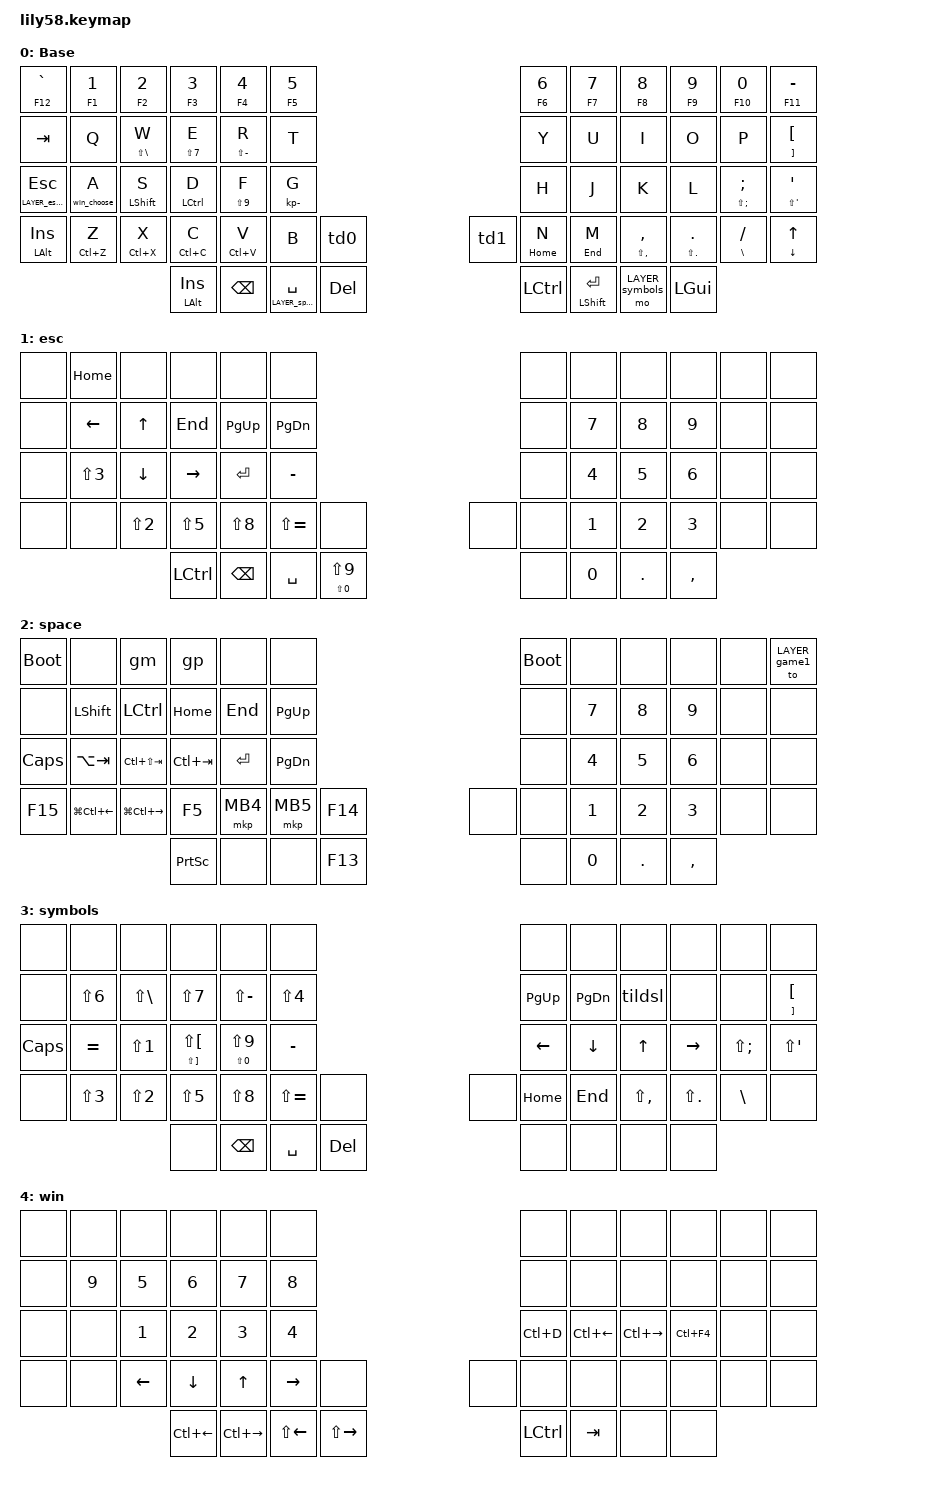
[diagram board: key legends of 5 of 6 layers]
/*
 * Copyright (c) 2020 The ZMK Contributors
 *
 * SPDX-License-Identifier: MIT
 */

#include <behaviors.dtsi>
#include <dt-bindings/zmk/keys.h>
#include <dt-bindings/zmk/bt.h>
#include <dt-bindings/zmk/ext_power.h>
#include <dt-bindings/zmk/pointing.h>

#define LAYER_Base 0
#define LAYER_esc_hold 1
#define LAYER_space_hold 2
#define LAYER_symbols 3
#define LAYER_a_windows 4
#define LAYER_game1 5

/* Key positions */

#define POS_LH_C1R1 0
#define POS_LH_C2R1 1
#define POS_LH_C3R1 2
#define POS_LH_C4R1 3
#define POS_LH_C5R1 4
#define POS_LH_C6R1 5
#define POS_RH_C1R1 6
#define POS_RH_C2R1 7
#define POS_RH_C3R1 8
#define POS_RH_C4R1 9
#define POS_RH_C5R1 10
#define POS_RH_C6R1 11
#define POS_LH_C1R2 12
#define POS_LH_C2R2 13
#define POS_LH_C3R2 14
#define POS_LH_C4R2 15
#define POS_LH_C5R2 16
#define POS_LH_C6R2 17
#define POS_RH_C1R2 18
#define POS_RH_C2R2 19
#define POS_RH_C3R2 20
#define POS_RH_C4R2 21
#define POS_RH_C5R2 22
#define POS_RH_C6R2 23
#define POS_LH_C1R3 24
#define POS_LH_C2R3 25
#define POS_LH_C3R3 26
#define POS_LH_C4R3 27
#define POS_LH_C5R3 28
#define POS_LH_C6R3 29
#define POS_RH_C1R3 30
#define POS_RH_C2R3 31
#define POS_RH_C3R3 32
#define POS_RH_C4R3 33
#define POS_RH_C5R3 34
#define POS_RH_C6R3 35
#define POS_LH_C1R4 36
#define POS_LH_C2R4 37
#define POS_LH_C3R4 38
#define POS_LH_C4R4 39
#define POS_LH_C5R4 40
#define POS_LH_C6R4 41
#define POS_RH_C1R4 42
#define POS_RH_C2R4 43
#define POS_RH_C3R4 44
#define POS_RH_C4R4 45
#define POS_RH_C5R4 46
#define POS_RH_C6R4 47
#define POS_LH_T1 48
#define POS_LH_T2 49
#define POS_LH_T3 50
#define POS_LH_T4 51
#define POS_LH_T5 52
#define POS_RH_T1 53
#define POS_RH_T2 54
#define POS_RH_T3 55
#define POS_RH_T4 56
#define POS_RH_T5 57

&mt {
    flavor = "tap-preferred";
    quick-tap-ms = <200>;
    require-prior-idle-ms = <100>;
    tapping-term-ms = <250>;
};

&lt {
    flavor = "tap-preferred";
    quick-tap-ms = <200>;
    require-prior-idle-ms = <100>;
};

/* Custom Defined Behaviors */
/ {
behaviors {
        td0: tap_dance_0 {
            compatible = "zmk,behavior-tap-dance";
            #binding-cells = <0>;
            tapping-term-ms = <200>;
            bindings = <&kp LC(LS(N1))>, <&kp LS(LG(LEFT))>, <&plapprove>;
        };
        td1: tap_dance_1 {
            compatible = "zmk,behavior-tap-dance";
            #binding-cells = <0>;
            tapping-term-ms = <200>;
            bindings = <&mkp LCLK>, <&lockwin>, <&plapprove>;
        };
};
};

/* Automatically generated macro definitions */
/ {
    macros {

        // windows and keypress
        win_choose: win_choose {
            label = "&WIN_CHOOSE";
            compatible = "zmk,behavior-macro";
            #binding-cells = <0>;
            tap-ms = <0>;
            wait-ms = <0>;
            bindings = <&macro_press>
                , <&mo LAYER_a_windows>
                , <&kp LGUI>
                , <&macro_pause_for_release>
                , <&macro_release>
                , <&mo LAYER_a_windows>
                , <&kp LGUI>;
        };

        // lock windows
        lockwin: lockwin {
            label = "&LOCKWIN";
            compatible = "zmk,behavior-macro";
            #binding-cells = <0>;
            tap-ms = <10>;
            wait-ms = <0>;
            bindings = <&macro_press>
                , <&kp LCTRL>
                , <&kp LALT>
                , <&macro_tap>
                , <&kp END>
                , <&macro_wait_time 2000>
                , <&macro_tap>
                , <&none>
                , <&macro_wait_time 1>
                , <&macro_release>
                , <&kp LALT>
                , <&kp LCTRL>
                , <&macro_tap>
                , <&kp RET>;
        };

        // please approve paste
        plapprove: plapprove {
            label = "&PLAPPROVE";
            compatible = "zmk,behavior-macro";
            #binding-cells = <0>;
            tap-ms = <20>;
            wait-ms = <30>;
            bindings = <&macro_tap>
                , <&kp P>
                , <&kp L>
                , <&kp E>
                , <&kp A>
                , <&kp S>
                , <&kp E>
                , <&kp SPACE>
                , <&kp A>
                , <&kp P>
                , <&kp P>
                , <&kp R>
                , <&kp O>
                , <&kp V>
                , <&kp E>
                , <&kp SPACE>
                , <&macro_tap>
                , <&kp LC(V)>
                , <&macro_wait_time 30>
                , <&macro_tap>
                , <&kp RET>;
        };

        // tilde slash
        tildsl: tildsl {
            label = "&TILDSL";
            compatible = "zmk,behavior-macro";
            #binding-cells = <0>;
            tap-ms = <30>;
            wait-ms = <30>;
            bindings = <&macro_tap>
                , <&kp LS(GRAVE)>
                , <&kp FSLH>;
        };

        // gp
        gp: gp {
            label = "&GP";
            compatible = "zmk,behavior-macro";
            #binding-cells = <0>;
            tap-ms = <30>;
            wait-ms = <30>;
            bindings = <&macro_tap>
                , <&kp G>
                , <&kp P>;
        };

        // gm
        gm: gm {
            label = "&GM";
            compatible = "zmk,behavior-macro";
            #binding-cells = <0>;
            tap-ms = <30>;
            wait-ms = <30>;
            bindings = <&macro_tap>
                , <&kp G>
                , <&kp M>;
        };
    };
};

/* Automatically generated behavior definitions */
/ {
    behaviors {


        // shift enter
        se: se {
            compatible = "zmk,behavior-hold-tap";
            #binding-cells = <2>;
            tapping-term-ms = <140>;
            bindings = <&kp>, <&kp>;
            quick-tap-ms = <150>;
        };

        // hold windows key and go to layer with numbers
        mtwc: mtwc {
            compatible = "zmk,behavior-hold-tap";
            #binding-cells = <2>;
            tapping-term-ms = <250>;
            bindings = <&win_choose>, <&kp>;
            flavor = "tap-preferred";
            quick-tap-ms = <200>;
            require-prior-idle-ms = <100>;
        };
    };
};

/ {
    combos {
        compatible = "zmk,combos";

        combo_F4 {
            key-positions = <POS_LH_C3R4 POS_LH_C5R4>;
            bindings = <&kp LA(F4)>;
            layers = <LAYER_space_hold>;
        };
    };
};


/ {
    keymap {
        compatible = "zmk,keymap";

        LAYER_Base {
            display-name = "Base";

            bindings = <
          &mt F12 GRAVE    &mt F1 N1       &mt F2 N2     &mt F3 N3        &mt F4 N4       &mt F5 N5                                                                                  &mt F6 N6          &mt F7 N7            &mt F8 N8        &mt F9 N9         &mt F10 N0    &mt F11 MINUS
                &kp TAB        &kp Q  &mt LS(BSLH) W  &mt LS(N7) E  &mt LS(MINUS) R           &kp T                                                                                      &kp Y              &kp U                &kp I            &kp O              &kp P    &mt RBKT LBKT
 &lt LAYER_esc_hold ESC    &mtwc 0 A     &mt LSHFT S   &mt LCTRL D     &mt LS(N9) F  &mt KP_MINUS G                                                                                      &kp H              &kp J                &kp K            &kp L  &mt LS(SEMI) SEMI  &mt LS(SQT) SQT
           &mt LALT INS  &mt LC(Z) Z     &mt LC(X) X   &mt LC(C) C      &mt LC(V) V           &kp B       &td0                                                              &td1    &mt HOME N          &mt END M  &mt LS(COMMA) COMMA  &mt LS(DOT) DOT      &mt BSLH FSLH      &mt DOWN UP
                                                      &mt LALT INS         &kp BSPC &lt LAYER_space_hold SPACE  &kp DEL                                               &kp LCTRL  &se LSHFT RET  &mo LAYER_symbols             &kp LGUI
            >;

            sensor-bindings = <&inc_dec_kp C_VOL_UP C_VOL_DN>;
        };

        LAYER_esc_hold {
            display-name = "esc";

            bindings = <
           &none    &kp HOME            &none       &none       &none          &none                                                                 &none    &none      &none   &none   &none   &none
           &none    &kp LEFT           &kp UP     &kp END   &kp PG_UP      &kp PG_DN                                                                 &none   &kp N7     &kp N8  &kp N9   &none   &none
           &none  &kp LS(N3)         &kp DOWN   &kp RIGHT     &kp RET      &kp MINUS                                                                 &none   &kp N4     &kp N5  &kp N6   &none   &none
           &none       &none       &kp LS(N2)  &kp LS(N5)  &kp LS(N8)  &kp LS(EQUAL)  &none                                            &none         &none   &kp N1     &kp N2  &kp N3   &none   &none
                                                            &kp LCTRL       &kp BSPC   &kp SPACE  &mt LS(N0) LS(N9)                    &none        &kp N0   &kp DOT &kp COMMA 
            >;

            sensor-bindings = <&inc_dec_kp C_VOL_UP C_VOL_DN>;
        };

        LAYER_space_hold {
            display-name = "space";

            bindings = <
 &bootloader             &none              &gm        &gp                 &none      &none                                                    &bootloader    &none      &none   &none   &none  &to LAYER_game1
       &none         &kp LSHFT          &kp LCTRL     &kp HOME           &kp END  &kp PG_UP                                                          &none   &kp N7     &kp N8  &kp N9   &none            &none
    &kp CAPS       &kp LA(TAB)    &kp LC(LS(TAB))  &kp LC(TAB)           &kp RET  &kp PG_DN                                                          &none   &kp N4     &kp N5  &kp N6   &none            &none
     &kp F15  &kp LG(LC(LEFT))  &kp LG(LC(RIGHT))       &kp F5          &mkp MB4   &mkp MB5   &kp F14                                        &none   &none   &kp N1     &kp N2  &kp N3   &none            &none
                                                     &kp PSCRN             &none      &none     &kp F13                                      &none  &kp N0   &kp DOT &kp COMMA 
            >;

            sensor-bindings = <&inc_dec_kp C_VOL_UP C_VOL_DN>;
        };
        LAYER_symbols {
            display-name = "symbols";

            bindings = <
    &none       &none         &none                  &none              &none          &none                                                           &none      &none          &none        &none         &none          &none
    &none  &kp LS(N6)  &kp LS(BSLH)             &kp LS(N7)      &kp LS(MINUS)     &kp LS(N4)                                                       &kp PG_UP  &kp PG_DN        &tildsl        &none         &none  &mt RBKT LBKT
 &kp CAPS   &kp EQUAL    &kp LS(N1)  &mt LS(RBKT) LS(LBKT)  &mt LS(N0) LS(N9)      &kp MINUS                                                        &kp LEFT   &kp DOWN         &kp UP    &kp RIGHT  &kp LS(SEMI)    &kp LS(SQT)
    &none  &kp LS(N3)    &kp LS(N2)             &kp LS(N5)         &kp LS(N8)  &kp LS(EQUAL)  &none                                         &none   &kp HOME    &kp END  &kp LS(COMMA)  &kp LS(DOT)      &kp BSLH          &none
                                                     &none          &kp BSPC       &kp SPACE  &kp DEL                                        &none     &none      &none          &none 
            >;

            sensor-bindings = <&inc_dec_kp C_VOL_UP C_VOL_DN>;
        };
        LAYER_a_windows {
            display-name = "win";

            bindings = <
  &none   &none     &none         &none          &none      &none                                                                       &none         &none          &none       &none   &none   &none
  &none  &kp N9    &kp N5        &kp N6         &kp N7     &kp N8                                                                       &none         &none          &none       &none   &none   &none
  &none   &none    &kp N1        &kp N2         &kp N3     &kp N4                                                                   &kp LC(D)  &kp LC(LEFT)  &kp LC(RIGHT)  &kp LC(F4)   &none   &none
  &none   &none  &kp LEFT      &kp DOWN         &kp UP  &kp RIGHT     &none                                                      &none  &none         &none          &none       &none   &none   &none
                                      &kp LC(LEFT)  &kp LC(RIGHT)   &kp LS(LEFT)  &kp LS(RIGHT)                                     &kp LCTRL       &kp TAB          &none       &none
            >;

            sensor-bindings = <&inc_dec_kp C_VOL_UP C_VOL_DN>;
        };
        LAYER_game1 {
            display-name = "clean";

            bindings = <
   &kp ESC  &mt F1 N1  &mt F2 N2  &mt F3 N3  &mt F4 N4  &mt F5 N5                                                                          &mt F6 N6  &mt F7 N7            &mt F8 N8        &mt F9 N9         &mt F10 N0    &mt F11 MINUS
   &kp TAB      &kp Q      &kp W      &kp E      &kp R      &kp T                                                                              &kp Y      &kp U                &kp I            &kp O              &kp P    &mt RBKT LBKT
 &kp LCTRL      &kp A      &kp S      &kp D      &kp F      &kp G                                                                              &kp H      &kp J                &kp K            &kp L  &mt LS(SEMI) SEMI  &mt LS(SQT) SQT
 &kp LSHFT      &kp Z      &kp X      &kp C      &kp V      &kp B                                                                              &kp N      &kp M  &mt LS(COMMA) COMMA  &mt LS(DOT) DOT      &mt BSLH FSLH      &mt DOWN UP
                                      &kp LALT   &kp BSPC   &kp SPACE  &kp DEL                                                &to LAYER_Base  &kp LCTRL  &se LSHFT RET &kp RET
            >;

            sensor-bindings = <&inc_dec_kp C_VOL_UP C_VOL_DN>;
        };
    };
};
